# SIMG301M114LIH register map
Vendor: Silicon Labs; Series: Si; File version: B
Registers are 32-bit, read-write, reset 0x0 unless marked. A register's access mark holds for its fields unless they carry their own. Offsets are from the block's base; [hi:lo] are bit positions; {n}, {i} and the like mark numbered series.

## L1ICACHE0_NS — L1ICACHE0_NS Registers
Base 0x40834000
Same registers: L1ICACHE0_S 0x50834000
0x00 IPVERSION ro reset 0x1 — The read only IPVERSION field gives the version for this module. There may be minor software changes required for modules with different values of IPVERSION.
  [31:0] IPVERSION — IP version ID
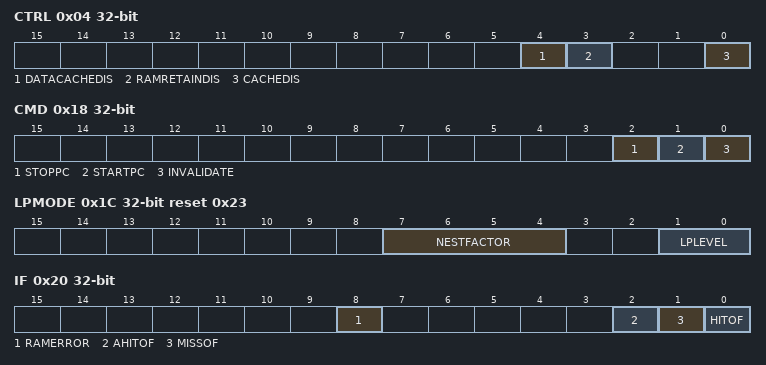
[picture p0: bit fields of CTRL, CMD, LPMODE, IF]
0x04 CTRL — Dynamically modifiable (When IP is running) Control Register
  [4] DATACACHEDIS — Data cache disable
  [3] RAMRETAINDIS — RAM retain disable
  [0] CACHEDIS — Cache Disable
0x08 PCHITS ro — Performance Counter Hits
0x0C PCMISSES ro — Performance Counter Misses
0x10 PCAHITS ro — Performance Counter Advanced Hits
0x14 STATUS ro
  [0] PCRUNNING
0x18 CMD wo — Software Modifiable Command Register
  [2] STOPPC — Stop Performance Counters
  [1] STARTPC — Start Performance Counters
  [0] INVALIDATE
0x1C LPMODE reset 0x23 — Low Power Mode Register
  [7:4] NESTFACTOR — Low Power Nest Factor
  [1:0] LPLEVEL — Low Power Level
    0=BASIC (Base instruction cache functionality); 1=ADVANCED (Advanced buffering mode, where the cache uses the fetch pattern to predict highly accessed data and store it in low-energy memory); 3=MINACTIVITY (Minimum activity mode, which allows the cache to minimize activity in logic that it predicts has a low probability being used. This mode can introduce wait-states into the instruction fetch stream when the cache exits one of its low-activity states. The number of wait-states introduced is small, but users running with 0-wait-state memory and wishing to reduce the variability that the cache might introduce with additional wait-states may wish to lower the cache low-power level. Note, this mode includes the advanced buffering mode functionality.)
0x20 IF — Interrupt Flag register
  [8] RAMERROR — RAM error Interrupt Flag
  [2] AHITOF — Advanced Hit Overflow Interrupt Flag
  [1] MISSOF — Miss Overflow Interrupt Flag
  [0] HITOF — Hit Overflow Interrupt Flag
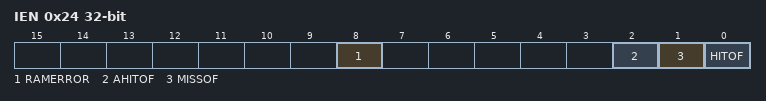
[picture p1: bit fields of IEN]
0x24 IEN — Interrupt Enable register
  [8] RAMERROR — RAM error Interrupt Enable
  [2] AHITOF — Advanced Hit Overflow Interrupt Enable
  [1] MISSOF — Miss Overflow Interrupt Enable
  [0] HITOF — Hit Overflow Interrupt Enable

## L2ICACHE0_NS — L2ICACHE0_NS Registers
Base 0x4085C000
Same registers: L2ICACHE0_S 0x5085C000
0x00 IPVERSION ro
  [31:0] IPVERSION — IP version ID
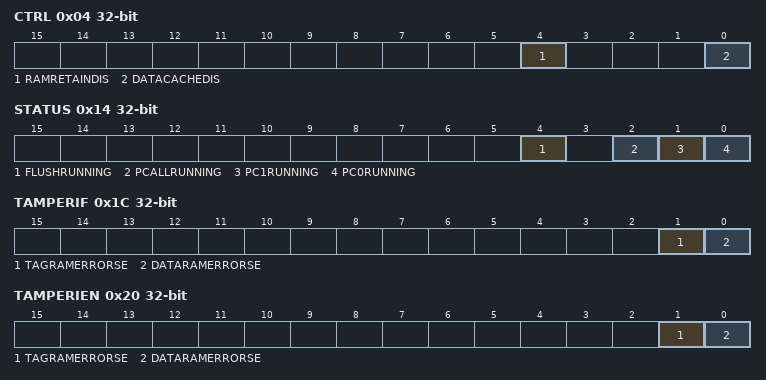
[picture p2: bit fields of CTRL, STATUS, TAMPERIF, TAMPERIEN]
0x04 CTRL — Root register
  [4] RAMRETAINDIS — RAM retain disable
  [0] DATACACHEDIS — Data cache disable
0x0C PRIORITY — Root register
  [7:0] MASTER — Master Arbitration Priority
    0=NONE; {v}=MASTER{v-1} (v=1..10)
0x14 STATUS ro
  [4] FLUSHRUNNING, [2] PCALLRUNNING, [1] PC1RUNNING, [0] PC0RUNNING
0x18 FLUSHCMD wo — Root register
  [0] FLUSHALL — Flush All Cache Lines
0x1C TAMPERIF — Root register
  [1] TAGRAMERRORSE — TAGRAM error Interrupt Flag
  [0] DATARAMERRORSE — DATARAM error Interrupt Flag
0x20 TAMPERIEN — Root register
  [1] TAGRAMERRORSE — TAGRAM error Interrupt Enable
  [0] DATARAMERRORSE — RAM error Interrupt Enable
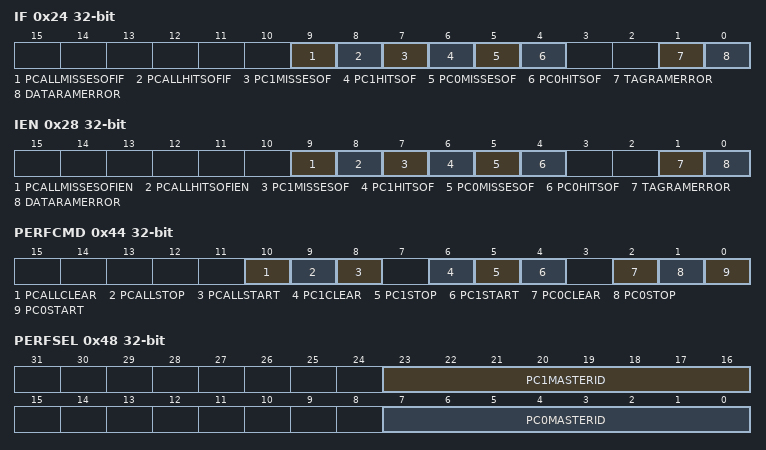
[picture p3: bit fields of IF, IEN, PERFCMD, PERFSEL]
0x24 IF
  [9] PCALLMISSESOFIF — PCALLMISSES Overflow Interrupt Flag
  [8] PCALLHITSOFIF — PCALLHITS Overflow Interrupt Flag
  [7] PC1MISSESOF — PC1MISSES Overflow Interrupt Flag
  [6] PC1HITSOF — PC1HITS Overflow Interrupt Flag
  [5] PC0MISSESOF — PC0MISSES Overflow Interrupt Flag
  [4] PC0HITSOF — PC0HITS Overflow Interrupt Flag
  [1] TAGRAMERROR — TAG RAM Error Interrupt Flag
  [0] DATARAMERROR — DATA RAM Error Interrupt Flag
0x28 IEN
  [9] PCALLMISSESOFIEN — PCALLMISSES Overflow Interrupt Enable
  [8] PCALLHITSOFIEN — PCALLHITS Overflow Interrupt Enable
  [7] PC1MISSESOF — PC1MISSES Overflow Interrupt Enable
  [6] PC1HITSOF — PC1HITS Overflow Interrupt Enable
  [5] PC0MISSESOF — PC0MISSES Overflow Interrupt Enable
  [4] PC0HITSOF — PC0HITS Overflow Interrupt Enable
  [1] TAGRAMERROR — TAG RAM Error Interrupt Enable
  [0] DATARAMERROR — DATA RAM Error Interrupt Enable
0x34 FLUSHADDRTOP — Root register
  [31:0] ADDR — Top Address
0x38 FLUSHADDRBOT — Root register
  [31:0] ADDR — Low Address
0x44 PERFCMD wo
  [10] PCALLCLEAR — CLEAR PerfRegall Counter
  [9] PCALLSTOP — Stop PerfRegall Counter
  [8] PCALLSTART — Start PerfRegall Counter
  [6] PC1CLEAR — CLEAR PerfReg1 Counter
  [5] PC1STOP — Stop PerfReg1 Counter
  [4] PC1START — Start PerfReg1 Counter
  [2] PC0CLEAR — CLEAR PerfReg0 Counter
  [1] PC0STOP — Stop PerfReg0 Counter
  [0] PC0START — Start PerfReg0 Counter
0x48 PERFSEL
  [23:16] PC1MASTERID — MasterID for PC1
  [7:0] PC0MASTERID — MasterID for PC0
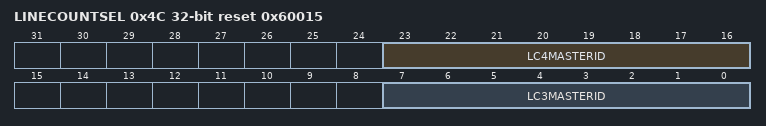
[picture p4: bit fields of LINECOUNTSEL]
0x4C LINECOUNTSEL reset 0x60015
  [23:16] LC4MASTERID — MasterID for MASTER3LC
  [7:0] LC3MASTERID — MasterID for MASTER3LC
0x64 PC0HITS ro
  [31:0] COUNT
0x68 PC0MISSES ro
  [31:0] COUNT
0x6C PC1HITS ro
  [31:0] COUNT
0x70 PC1MISSES ro
  [31:0] COUNT
0x74 PCALLHITS ro
  [31:0] COUNT
0x78 PCALLMISSES ro
  [31:0] COUNT
{0x84+4i} MASTER{i}LC ro (i=0..4)
  [15:0] COUNT — Cache Line Count
0x98 MASTERSLC ro
  [15:0] COUNT — Cache Line Count
